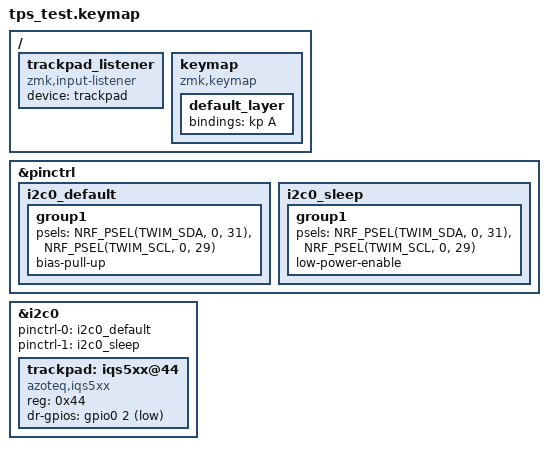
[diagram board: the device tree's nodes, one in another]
#include <behaviors.dtsi>
#include <dt-bindings/zmk/keys.h>
#include <dt-bindings/zmk/pointing.h>

&pinctrl {
    i2c0_default: i2c0_default {
        group1 {
            psels = <NRF_PSEL(TWIM_SDA, 0, 31)>, 
                    <NRF_PSEL(TWIM_SCL, 0, 29)>;
            bias-pull-up; 
        };
    };
    i2c0_sleep: i2c0_sleep {
        group1 {
            psels = <NRF_PSEL(TWIM_SDA, 0, 31)>,
                    <NRF_PSEL(TWIM_SCL, 0, 29)>;
            low-power-enable;
        };
    };
};

&i2c0 {
    status = "okay";
    pinctrl-0 = <&i2c0_default>;
    pinctrl-1 = <&i2c0_sleep>;
    pinctrl-names = "default", "sleep";

    trackpad: iqs5xx@44 {
        compatible = "azoteq,iqs5xx";
        reg = <0x44>;
        dr-gpios = <&gpio0 2 (GPIO_ACTIVE_LOW | GPIO_PULL_UP)>; 
    };
};

/ {
    trackpad_listener {
        compatible = "zmk,input-listener";
        device = <&trackpad>;
    };

    keymap {
        compatible = "zmk,keymap";
        default_layer {
            bindings = <&kp A>;
        };
    };
};
